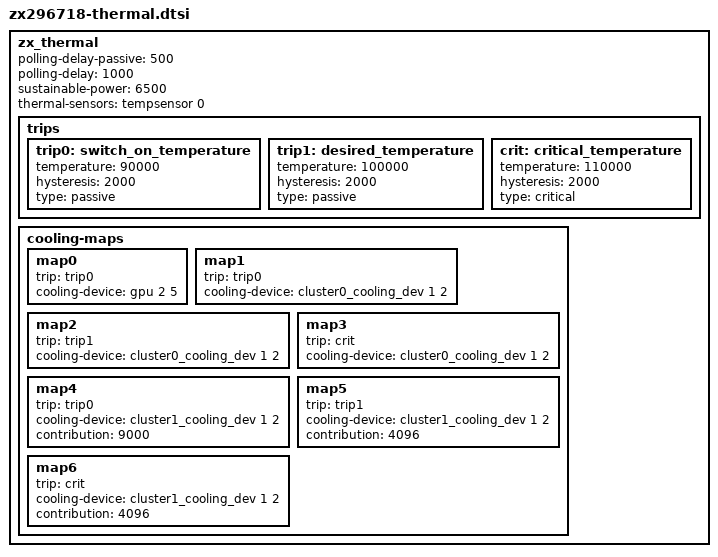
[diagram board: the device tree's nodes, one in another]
/*
 * Device Tree Source for ZX296718 SoC thermal
 *
 * Copyright (c) 2016, Jun Nie <jun.nie@linaro.org>
 *
 * This file is licensed under the terms of the GNU General Public License
 * version 2.  This program is licensed "as is" without any warranty of any
 * kind, whether express or implied.
 */

#include <dt-bindings/thermal/thermal.h>

zx_thermal: zx_thermal {
	polling-delay-passive = <500>; /* milliseconds */
	polling-delay = <1000>; /* milliseconds */
	sustainable-power = <6500>;

	thermal-sensors = <&tempsensor 0>;

	trips {
		trip0: switch_on_temperature {
			temperature = <90000>; /* millicelsius */
			hysteresis = <2000>; /* millicelsius */
			type = "passive";
		};

		trip1: desired_temperature {
			temperature = <100000>; /* millicelsius */
			hysteresis = <2000>; /* millicelsius */
			type = "passive";
		};

		crit: critical_temperature {
			temperature = <110000>; /* millicelsius */
			hysteresis = <2000>; /* millicelsius */
			type = "critical";
		};
	};

	cooling-maps {
		map0 {
			trip = <&trip0>;
			cooling-device =
				<&gpu 2 5>;
		};

		map1 {
			trip = <&trip0>;
			cooling-device = <&cluster0_cooling_dev 1 2>;
		};

		map2 {
			trip = <&trip1>;
			cooling-device = <&cluster0_cooling_dev 1 2>;
		};

		map3 {
			trip = <&crit>;
			cooling-device = <&cluster0_cooling_dev 1 2>;
		};

		map4 {
			trip = <&trip0>;
			cooling-device = <&cluster1_cooling_dev 1 2>;
			contribution = <9000>;
		};

		map5 {
			trip = <&trip1>;
			cooling-device = <&cluster1_cooling_dev 1 2>;
			contribution = <4096>;
		};

		map6 {
			trip = <&crit>;
			cooling-device = <&cluster1_cooling_dev 1 2>;
			contribution = <4096>;
		};
	};
};
